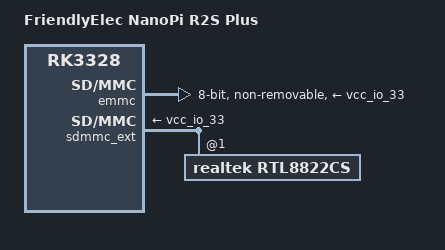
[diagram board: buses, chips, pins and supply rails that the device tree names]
// SPDX-License-Identifier: GPL-2.0-or-later OR MIT
/*
 * Copyright (c) 2021 FriendlyElec Computer Tech. Co., Ltd.
 * (http://www.friendlyarm.com)
 *
 * Copyright (c) 2023 FriendlyElec Computer Tech. Co., Ltd.
 * (http://www.friendlyarm.com)
 *
 * Copyright (c) 2023 Zhennan Li <i@nanmu.me>
 */

/dts-v1/;
#include "rk3328-nanopi-r2s.dts"

/ {
	model = "FriendlyElec NanoPi R2S Plus";
	compatible = "friendlyarm,nanopi-r2s-plus", "rockchip,rk3328";

	aliases {
		mmc1 = &emmc;
	};
};

&emmc {
	bus-width = <8>;
	cap-mmc-highspeed;
	max-frequency = <150000000>;
	mmc-ddr-1_8v;
	mmc-hs200-1_8v;
	non-removable;
	pinctrl-names = "default";
	pinctrl-0 = <&emmc_clk &emmc_cmd &emmc_bus8>;
	vmmc-supply = <&vcc_io_33>;
	vqmmc-supply = <&vcc18_emmc>;
	status = "okay";
};

&sdmmc_ext {
	vmmc-supply = <&vcc_io_33>;
	vqmmc-supply = <&vcc_18>;
	max-frequency = <150000000>;
	sd-uhs-sdr104;
	status = "okay";

	rtl8822cs@1 {
		reg = <1>;
		compatible = "realtek,rtl8822cs";
	};
};
